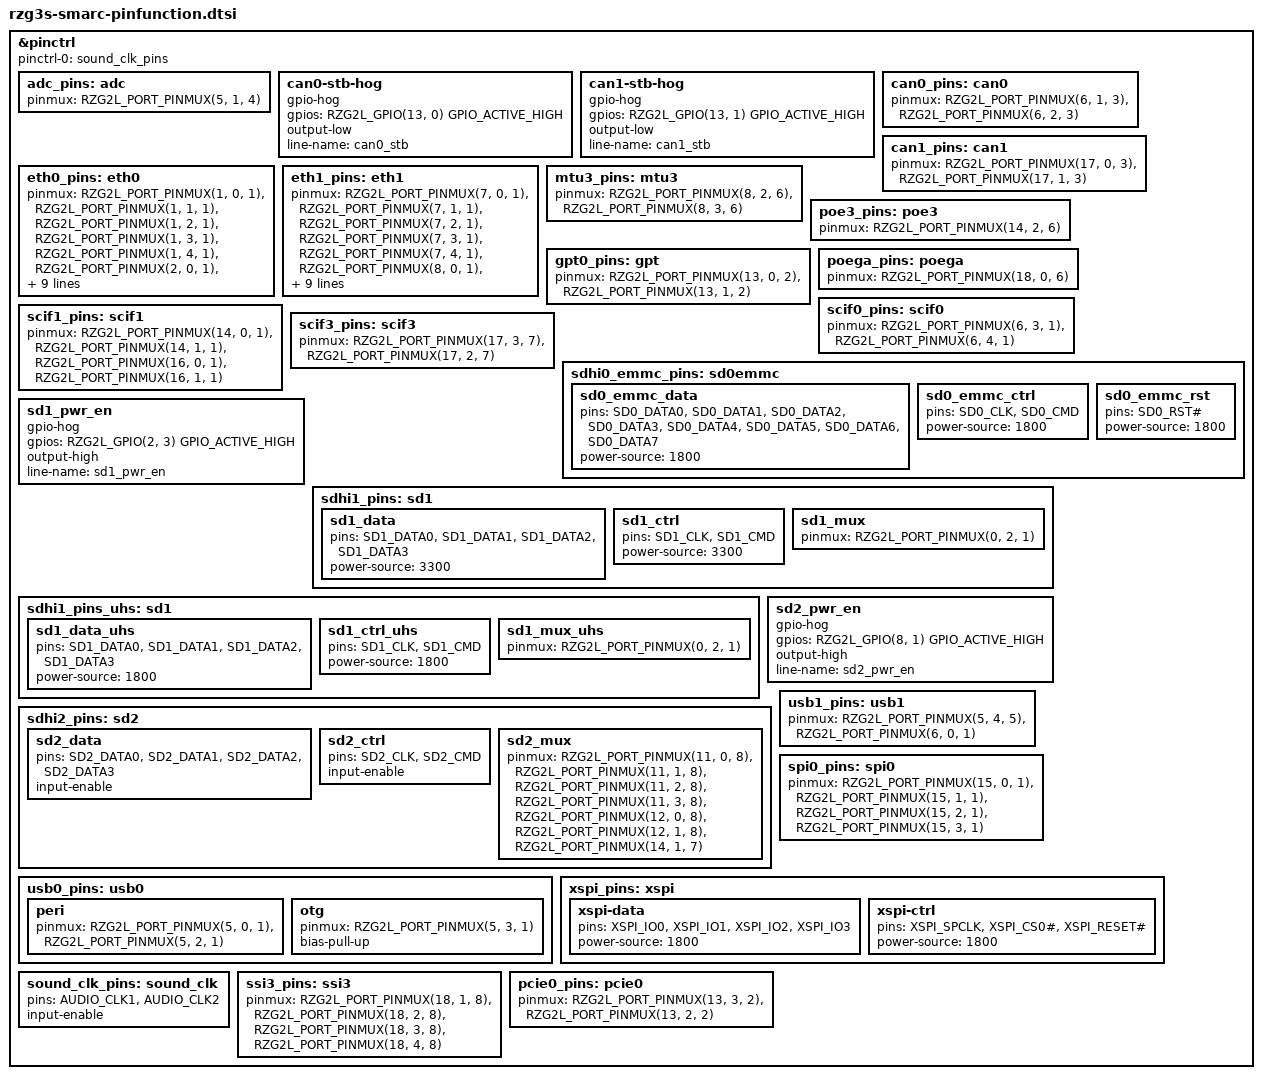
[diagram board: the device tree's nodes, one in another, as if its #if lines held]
// SPDX-License-Identifier: (GPL-2.0-only OR BSD-2-Clause)
/*
 * Device Tree Source for configuration of  RZ/G3S SMARC pins.
 *
 * Copyright (C) 2023 Renesas Electronics Corp.
 */

#include <dt-bindings/gpio/gpio.h>
#include <dt-bindings/pinctrl/rzg2l-pinctrl.h>

&pinctrl {
	pinctrl-0 = <&sound_clk_pins>;
	pinctrl-names = "default";

	adc_pins: adc {
		pinmux = <RZG2L_PORT_PINMUX(5, 1, 4)>; /* ADC_TRG */
	};

#if SW_GPIO_CAN_PMOD
	/* GPIO8 */
	can0-stb-hog {
		gpio-hog;
		gpios = <RZG2L_GPIO(13, 0) GPIO_ACTIVE_HIGH>;
		output-low;
		line-name = "can0_stb";
	};

	/* GPIO9 */
	can1-stb-hog {
		gpio-hog;
		gpios = <RZG2L_GPIO(13, 1) GPIO_ACTIVE_HIGH>;
		output-low;
		line-name = "can1_stb";
	};
#endif

	can0_pins: can0 {
		pinmux = <RZG2L_PORT_PINMUX(6, 1, 3)>, /* TX */
			 <RZG2L_PORT_PINMUX(6, 2, 3)>; /* RX */
	};

	can1_pins: can1 {
		pinmux = <RZG2L_PORT_PINMUX(17, 0, 3)>, /* TX */
			 <RZG2L_PORT_PINMUX(17, 1, 3)>; /* RX */
	};

	eth0_pins: eth0 {
		pinmux = <RZG2L_PORT_PINMUX(1, 0, 1)>, /* ET0_TXC */
			 <RZG2L_PORT_PINMUX(1, 1, 1)>, /* ET0_TX_CTL */
			 <RZG2L_PORT_PINMUX(1, 2, 1)>, /* ET0_TXD0 */
			 <RZG2L_PORT_PINMUX(1, 3, 1)>, /* ET0_TXD1 */
			 <RZG2L_PORT_PINMUX(1, 4, 1)>, /* ET0_TXD2 */
			 <RZG2L_PORT_PINMUX(2, 0, 1)>, /* ET0_TXD3 */
			 <RZG2L_PORT_PINMUX(3, 0, 1)>, /* ET0_RXC */
			 <RZG2L_PORT_PINMUX(3, 1, 1)>, /* ET0_RX_CTL */
			 <RZG2L_PORT_PINMUX(3, 2, 1)>, /* ET0_RXD0 */
			 <RZG2L_PORT_PINMUX(3, 3, 1)>, /* ET0_RXD1 */
			 <RZG2L_PORT_PINMUX(4, 0, 1)>, /* ET0_RXD2 */
			 <RZG2L_PORT_PINMUX(4, 1, 1)>, /* ET0_RXD3 */
			 <RZG2L_PORT_PINMUX(4, 3, 1)>, /* ET0_MDC */
			 <RZG2L_PORT_PINMUX(4, 4, 1)>, /* ET0_MDIO */
			 <RZG2L_PORT_PINMUX(4, 5, 1)>; /* ET0_LINKSTA */
	};

	eth1_pins: eth1 {
		pinmux = <RZG2L_PORT_PINMUX(7, 0, 1)>, /* ET1_TXC */
			 <RZG2L_PORT_PINMUX(7, 1, 1)>, /* ET1_TX_CTL */
			 <RZG2L_PORT_PINMUX(7, 2, 1)>, /* ET1_TXD0 */
			 <RZG2L_PORT_PINMUX(7, 3, 1)>, /* ET1_TXD1 */
			 <RZG2L_PORT_PINMUX(7, 4, 1)>, /* ET1_TXD2 */
			 <RZG2L_PORT_PINMUX(8, 0, 1)>, /* ET1_TXD3 */
			 <RZG2L_PORT_PINMUX(8, 4, 1)>, /* ET1_RXC */
			 <RZG2L_PORT_PINMUX(9, 0, 1)>, /* ET1_RX_CTL */
			 <RZG2L_PORT_PINMUX(9, 1, 1)>, /* ET1_RXD0 */
			 <RZG2L_PORT_PINMUX(9, 2, 1)>, /* ET1_RXD1 */
			 <RZG2L_PORT_PINMUX(9, 3, 1)>, /* ET1_RXD2 */
			 <RZG2L_PORT_PINMUX(10, 0, 1)>, /* ET1_RXD3 */
			 <RZG2L_PORT_PINMUX(10, 2, 1)>, /* ET1_MDC */
			 <RZG2L_PORT_PINMUX(10, 3, 1)>, /* ET1_MDIO */
			 <RZG2L_PORT_PINMUX(10, 4, 1)>; /* ET1_LINKSTA */
	};

#if MTU3_PWM_SUPPORT
	mtu3_pins: mtu3 {
		pinmux = <RZG2L_PORT_PINMUX(8, 2, 6)>, /* MTIOC7C - GPIO12 */
			 <RZG2L_PORT_PINMUX(8, 3, 6)>; /* MTIOC7D - GPIO13 */
	};
#endif

#if MTU3_COMPLEMENTARY_PWM_SEL
	poe3_pins: poe3 {
		pinmux = <RZG2L_PORT_PINMUX(14, 2, 6)>; /* POE10# - GPIO11 */
	};
#endif

	gpt0_pins: gpt {
		pinmux = <RZG2L_PORT_PINMUX(13, 0, 2)>, /* GTIOC0A - GPIO8 */
			 <RZG2L_PORT_PINMUX(13, 1, 2)>; /* GTIOC0B - GPIO9 */
	};

	poega_pins: poega {
		pinmux = <RZG2L_PORT_PINMUX(18, 0, 6)>; /* GTERGA - GPIO4 */
	};

	scif0_pins: scif0 {
		pinmux = <RZG2L_PORT_PINMUX(6, 3, 1)>, /* TXD */
			 <RZG2L_PORT_PINMUX(6, 4, 1)>; /* RXD */
	};

#if !SD2_SEL && !SPDIF_SEL
	scif1_pins: scif1 {
		pinmux = <RZG2L_PORT_PINMUX(14, 0, 1)>, /* TXD */
			 <RZG2L_PORT_PINMUX(14, 1, 1)>, /* RXD */
			 <RZG2L_PORT_PINMUX(16, 0, 1)>, /* CTS# */
			 <RZG2L_PORT_PINMUX(16, 1, 1)>; /* RTS# */
	};
#elif SPDIF_SEL
	spdif_pins: spdif {
		pinmux = <RZG2L_PORT_PINMUX(16, 0, 2)>, /* SPDIF_IN */
			 <RZG2L_PORT_PINMUX(16, 1, 2)>; /* SPDIF_OUT */
	};
#endif

	scif3_pins: scif3 {
		pinmux = <RZG2L_PORT_PINMUX(17, 3, 7)>, /* TXD */
			 <RZG2L_PORT_PINMUX(17, 2, 7)>; /* RXD */
	};

#if !SW_SD0_DEV_SEL
	sdhi0_emmc_pins: sd0emmc {
		sd0_emmc_data {
			pins = "SD0_DATA0", "SD0_DATA1", "SD0_DATA2",
				"SD0_DATA3", "SD0_DATA4", "SD0_DATA5",
				"SD0_DATA6", "SD0_DATA7";
			power-source = <1800>;
		};

		sd0_emmc_ctrl {
			pins = "SD0_CLK", "SD0_CMD";
			power-source = <1800>;
		};

		sd0_emmc_rst {
			pins = "SD0_RST#";
			power-source = <1800>;
		};
	};
#else
	sd0_pwr_en {
		gpio-hog;
		gpios = <RZG2L_GPIO(2, 1) GPIO_ACTIVE_HIGH>;
		output-high;
		line-name = "sd0_pwr_en";
	};

	sdhi0_pins: sd0 {
		sd0_data {
			pins = "SD0_DATA0", "SD0_DATA1", "SD0_DATA2", "SD0_DATA3";
			power-source = <3300>;
		};

		sd0_ctrl {
			pins = "SD0_CLK", "SD0_CMD";
			power-source = <3300>;
		};

		sd0_mux {
			pinmux = <RZG2L_PORT_PINMUX(0, 0, 1)>; /* SD0_CD */
		};
	};

	sdhi0_uhs_pins: sd0 {
		sd0_data_uhs {
			pins = "SD0_DATA0", "SD0_DATA1", "SD0_DATA2", "SD0_DATA3";
			power-source = <1800>;
		};

		sd0_ctrl_uhs {
			pins = "SD0_CLK", "SD0_CMD";
			power-source = <1800>;
		};

		sd0_mux_uhs {
			pinmux = <RZG2L_PORT_PINMUX(0, 0, 1)>; /* SD0_CD */
		};
	};
#endif

	sd1_pwr_en {
		gpio-hog;
		gpios = <RZG2L_GPIO(2, 3) GPIO_ACTIVE_HIGH>; /* SDIO_PWR_EN */
		output-high;
		line-name = "sd1_pwr_en";
	};

	sdhi1_pins: sd1 {
		sd1_data {
			pins = "SD1_DATA0", "SD1_DATA1", "SD1_DATA2", "SD1_DATA3";
			power-source = <3300>;
		};

		sd1_ctrl {
			pins = "SD1_CLK", "SD1_CMD";
			power-source = <3300>;
		};

		sd1_mux {
			pinmux = <RZG2L_PORT_PINMUX(0, 2, 1)>; /* SD1_CD */
		};
	};

	sdhi1_pins_uhs: sd1 {
		sd1_data_uhs {
			pins = "SD1_DATA0", "SD1_DATA1", "SD1_DATA2", "SD1_DATA3";
			power-source = <1800>;
		};

		sd1_ctrl_uhs {
			pins = "SD1_CLK", "SD1_CMD";
			power-source = <1800>;
		};

		sd1_mux_uhs {
			pinmux = <RZG2L_PORT_PINMUX(0, 2, 1)>; /* SD1_CD */
		};
	};

#if SD2_SEL
	sd2_pwr_en {
		gpio-hog;
		gpios = <RZG2L_GPIO(8, 1) GPIO_ACTIVE_HIGH>;
		output-high;
		line-name = "sd2_pwr_en";
	};

	sdhi2_pins: sd2 {
		sd2_data {
			pins = "SD2_DATA0", "SD2_DATA1", "SD2_DATA2", "SD2_DATA3";
			input-enable;
		};

		sd2_ctrl {
			pins = "SD2_CLK", "SD2_CMD";
			input-enable;
		};

		sd2_mux {
			pinmux = <RZG2L_PORT_PINMUX(11, 0, 8)>, /* SD2_CLK */
				 <RZG2L_PORT_PINMUX(11, 1, 8)>, /* SD2_CMD */
				 <RZG2L_PORT_PINMUX(11, 2, 8)>, /* SD2_DATA0 */
				 <RZG2L_PORT_PINMUX(11, 3, 8)>, /* SD2_DATA1 */
				 <RZG2L_PORT_PINMUX(12, 0, 8)>, /* SD2_DATA2 */
				 <RZG2L_PORT_PINMUX(12, 1, 8)>, /* SD2_DATA3 */
				 <RZG2L_PORT_PINMUX(14, 1, 7)>; /* SD2_CD# */
		};
	};
#endif

	usb0_pins: usb0 {
		peri {
			pinmux = <RZG2L_PORT_PINMUX(5, 0, 1)>, /* VBUS */
				 <RZG2L_PORT_PINMUX(5, 2, 1)>; /* OVC */
		};

		otg {
			pinmux = <RZG2L_PORT_PINMUX(5, 3, 1)>; /* OTG_ID */
			bias-pull-up;
		};
	};

	usb1_pins: usb1 {
		pinmux = <RZG2L_PORT_PINMUX(5, 4, 5)>, /* OVC */
			 <RZG2L_PORT_PINMUX(6, 0, 1)>; /* VBUS */
	};

	spi0_pins: spi0 {
		pinmux = <RZG2L_PORT_PINMUX(15, 0, 1)>, /* CK */
			 <RZG2L_PORT_PINMUX(15, 1, 1)>, /* MOSI */
			 <RZG2L_PORT_PINMUX(15, 2, 1)>, /* MISO */
			 <RZG2L_PORT_PINMUX(15, 3, 1)>; /* SSL */
	};

	xspi_pins: xspi {
		xspi-data {
			pins = "XSPI_IO0", "XSPI_IO1", "XSPI_IO2", "XSPI_IO3";
			power-source = <1800>;
		};

		xspi-ctrl {
			pins = "XSPI_SPCLK", "XSPI_CS0#", "XSPI_RESET#";
			power-source = <1800>;
		};
	};

	sound_clk_pins: sound_clk {
		pins = "AUDIO_CLK1", "AUDIO_CLK2";
		input-enable;
	};

	ssi3_pins: ssi3 {
		pinmux = <RZG2L_PORT_PINMUX(18, 1, 8)>, /* BCK */
			 <RZG2L_PORT_PINMUX(18, 2, 8)>, /* RCK */
			 <RZG2L_PORT_PINMUX(18, 3, 8)>, /* TXD */
			 <RZG2L_PORT_PINMUX(18, 4, 8)>; /* RXD */
	};

	pcie0_pins: pcie0 {
		pinmux = <RZG2L_PORT_PINMUX(13, 3, 2)>, /* PCIE_CLKREQ_N */
			 <RZG2L_PORT_PINMUX(13, 2, 2)>; /* PCIE_RST_OUT# */
	};
};
